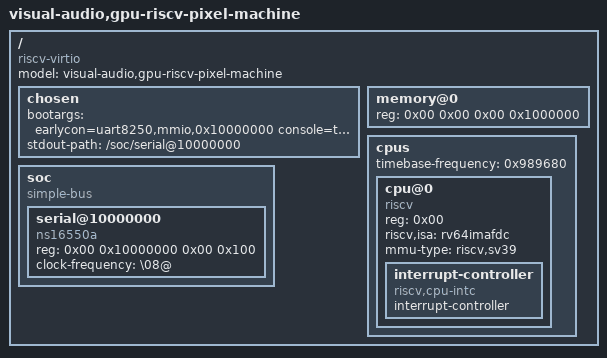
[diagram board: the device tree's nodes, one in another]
/dts-v1/;

/ {
	#address-cells = <0x02>;
	#size-cells = <0x02>;
	compatible = "riscv-virtio";
	model = "visual-audio,gpu-riscv-pixel-machine";

	chosen {
		bootargs = "earlycon=uart8250,mmio,0x10000000 console=ttyS0";
		stdout-path = "/soc/serial@10000000";
	};

	memory@0 {
		device_type = "memory";
		reg = <0x00 0x00 0x00 0x1000000>;
	};

	cpus {
		#address-cells = <0x01>;
		#size-cells = <0x00>;
		timebase-frequency = <0x989680>;

		cpu@0 {
			device_type = "cpu";
			reg = <0x00>;
			status = "okay";
			compatible = "riscv";
			riscv,isa = "rv64imafdc";
			mmu-type = "riscv,sv39";

			interrupt-controller {
				#interrupt-cells = <0x01>;
				interrupt-controller;
				compatible = "riscv,cpu-intc";
				phandle = <0x01>;
			};
		};
	};

	soc {
		#address-cells = <0x02>;
		#size-cells = <0x02>;
		compatible = "simple-bus";
		ranges;

		serial@10000000 {
			compatible = "ns16550a";
			reg = <0x00 0x10000000 0x00 0x100>;
			clock-frequency = "\08@";
		};
	};
};
